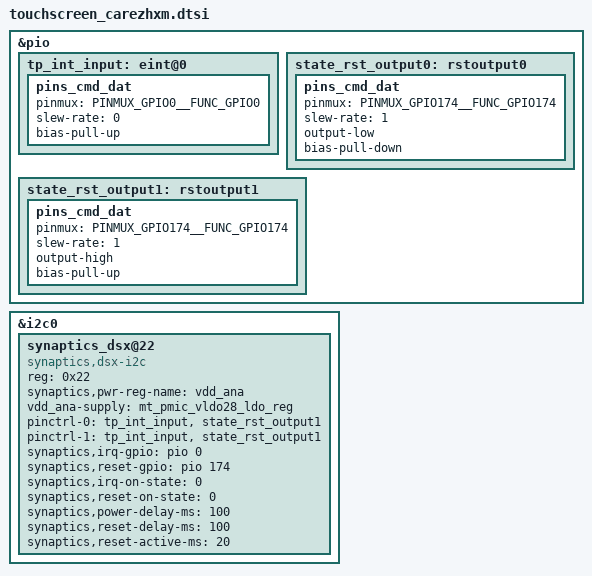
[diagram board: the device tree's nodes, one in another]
&pio {
	tp_int_input: eint@0 {
		pins_cmd_dat {
			pinmux = <PINMUX_GPIO0__FUNC_GPIO0>;
			slew-rate = <0>;
			bias-pull-up;
		};
	};

	state_rst_output0: rstoutput0 {
		pins_cmd_dat {
			pinmux = <PINMUX_GPIO174__FUNC_GPIO174>;
			slew-rate = <1>;
			output-low;
			bias-pull-down;
		};
	};

	state_rst_output1: rstoutput1 {
		pins_cmd_dat {
			pinmux = <PINMUX_GPIO174__FUNC_GPIO174>;
			slew-rate = <1>;
			output-high;
			bias-pull-up;
		};
	};
};

&i2c0 {
	status = "okay";
	synaptics_dsx@22 {
	compatible = "synaptics,dsx-i2c";
	reg = <0x22>;
	synaptics,pwr-reg-name = "vdd_ana";
	vdd_ana-supply = <&mt_pmic_vldo28_ldo_reg>;
	pinctrl-names = "pmx_ts_active", "pmx_ts_suspend";
	pinctrl-0 = <&tp_int_input &state_rst_output1>;
	pinctrl-1 = <&tp_int_input &state_rst_output1>;
	synaptics,irq-gpio = <&pio 0 0x2008>;
	synaptics,reset-gpio = <&pio 174 0x00>;
	synaptics,irq-on-state = <0>;
	synaptics,reset-on-state = <0>;
	synaptics,power-delay-ms = <100>;
	synaptics,reset-delay-ms = <100>;
	synaptics,reset-active-ms = <20>;
	};
};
